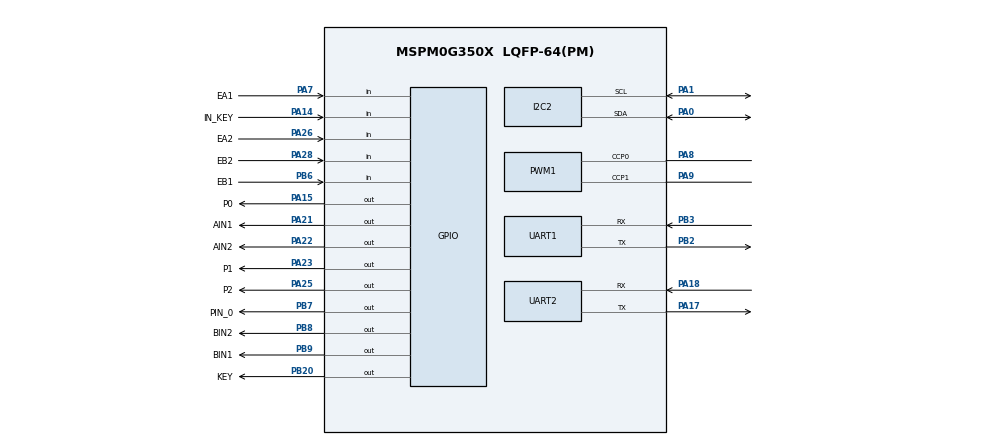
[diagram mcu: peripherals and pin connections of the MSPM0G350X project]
/**
 * @cliArgs --device "MSPM0G350X" --part "Default" --package "LQFP-64(PM)" --product "mspm0_sdk@2.10.00.04"
 * @versions {"tool":"1.27.1+4634"}
 */

/**
 * Import the modules used in this configuration.
 */
const ADC12   = scripting.addModule("/ti/driverlib/ADC12", {}, false);
const ADC121  = ADC12.addInstance();
const GPIO    = scripting.addModule("/ti/driverlib/GPIO", {}, false);
const GPIO1   = GPIO.addInstance();
const GPIO2   = GPIO.addInstance();
const GPIO3   = GPIO.addInstance();
const GPIO4   = GPIO.addInstance();
const GPIO5   = GPIO.addInstance();
const GPIO6   = GPIO.addInstance();
const GPIO7   = GPIO.addInstance();
const I2C     = scripting.addModule("/ti/driverlib/I2C", {}, false);
const I2C1    = I2C.addInstance();
const I2C2    = I2C.addInstance();
const PWM     = scripting.addModule("/ti/driverlib/PWM", {}, false);
const PWM1    = PWM.addInstance();
const SYSCTL  = scripting.addModule("/ti/driverlib/SYSCTL");
const SYSTICK = scripting.addModule("/ti/driverlib/SYSTICK");
const TIMER   = scripting.addModule("/ti/driverlib/TIMER", {}, false);
const TIMER1  = TIMER.addInstance();
const UART    = scripting.addModule("/ti/driverlib/UART", {}, false);
const UART1   = UART.addInstance();
const UART2   = UART.addInstance();

/**
 * Write custom configuration values to the imported modules.
 */
ADC121.$name                             = "ADC_VOLTAGE";
ADC121.sampClkSrc                        = "DL_ADC12_CLOCK_ULPCLK";
ADC121.sampClkDiv                        = "DL_ADC12_CLOCK_DIVIDE_8";
ADC121.repeatMode                        = true;
ADC121.sampleTime0                       = "2us";
ADC121.configureDMA                      = true;
ADC121.sampCnt                           = 1;
ADC121.enabledDMATriggers                = ["DL_ADC12_DMA_MEM0_RESULT_LOADED"];
ADC121.peripheral.adcPin0.$assign        = "PA27";
ADC121.adcPin0Config.hideOutputInversion = scripting.forceWrite(false);
ADC121.adcPin0Config.$name               = "ti_driverlib_gpio_GPIOPinGeneric4";
ADC121.DMA_CHANNEL.$name                 = "DMA_CH0";
ADC121.DMA_CHANNEL.addressMode           = "f2b";
ADC121.DMA_CHANNEL.srcLength             = "HALF_WORD";
ADC121.DMA_CHANNEL.dstLength             = "HALF_WORD";
ADC121.DMA_CHANNEL.configureTransferSize = true;
ADC121.DMA_CHANNEL.transferSize          = 40;
ADC121.DMA_CHANNEL.transferMode          = "FULL_CH_REPEAT_SINGLE";

const Board = scripting.addModule("/ti/driverlib/Board", {}, false);

GPIO1.$name                         = "GPIO_MOTOR";
GPIO1.associatedPins.create(5);
GPIO1.associatedPins[0].$name       = "BIN2";
GPIO1.associatedPins[0].pin.$assign = "PB8";
GPIO1.associatedPins[1].$name       = "BIN1";
GPIO1.associatedPins[1].pin.$assign = "PB9";
GPIO1.associatedPins[2].$name       = "AIN1";
GPIO1.associatedPins[2].pin.$assign = "PA21";
GPIO1.associatedPins[3].$name       = "AIN2";
GPIO1.associatedPins[3].pin.$assign = "PA22";
GPIO1.associatedPins[4].$name       = "PIN_STBY";

GPIO2.$name                         = "Gray_Address";
GPIO2.associatedPins.create(3);
GPIO2.associatedPins[0].$name       = "P0";
GPIO2.associatedPins[0].pin.$assign = "PA15";
GPIO2.associatedPins[1].$name       = "P1";
GPIO2.associatedPins[1].pin.$assign = "PA23";
GPIO2.associatedPins[2].$name       = "P2";
GPIO2.associatedPins[2].pin.$assign = "PA25";

GPIO3.$name                         = "LED";
GPIO3.associatedPins[0].$name       = "KEY";
GPIO3.associatedPins[0].pin.$assign = "PB20";

GPIO4.$name                               = "GRAY_IN";
GPIO4.associatedPins[0].$name             = "IN_KEY";
GPIO4.associatedPins[0].direction         = "INPUT";
GPIO4.associatedPins[0].internalResistor  = "PULL_UP";
GPIO4.associatedPins[0].interruptEn       = true;
GPIO4.associatedPins[0].polarity          = "FALL";
GPIO4.associatedPins[0].interruptPriority = "1";
GPIO4.associatedPins[0].pin.$assign       = "PA14";

GPIO5.$name                               = "ENCODERA";
GPIO5.associatedPins.create(2);
GPIO5.associatedPins[0].$name             = "EA1";
GPIO5.associatedPins[0].direction         = "INPUT";
GPIO5.associatedPins[0].interruptEn       = true;
GPIO5.associatedPins[0].polarity          = "RISE";
GPIO5.associatedPins[0].interruptPriority = "1";
GPIO5.associatedPins[0].internalResistor  = "PULL_UP";
GPIO5.associatedPins[0].pin.$assign       = "PA7";
GPIO5.associatedPins[1].$name             = "EA2";
GPIO5.associatedPins[1].direction         = "INPUT";
GPIO5.associatedPins[1].interruptEn       = true;
GPIO5.associatedPins[1].polarity          = "RISE";
GPIO5.associatedPins[1].interruptPriority = "1";
GPIO5.associatedPins[1].internalResistor  = "PULL_UP";
GPIO5.associatedPins[1].pin.$assign       = "PA26";

GPIO6.$name                               = "ENCODERB";
GPIO6.associatedPins.create(2);
GPIO6.associatedPins[0].$name             = "EB1";
GPIO6.associatedPins[0].direction         = "INPUT";
GPIO6.associatedPins[0].interruptEn       = true;
GPIO6.associatedPins[0].polarity          = "RISE";
GPIO6.associatedPins[0].interruptPriority = "1";
GPIO6.associatedPins[0].internalResistor  = "PULL_UP";
GPIO6.associatedPins[0].pin.$assign       = "PB6";
GPIO6.associatedPins[1].$name             = "EB2";
GPIO6.associatedPins[1].direction         = "INPUT";
GPIO6.associatedPins[1].interruptEn       = true;
GPIO6.associatedPins[1].polarity          = "RISE";
GPIO6.associatedPins[1].interruptPriority = "1";
GPIO6.associatedPins[1].internalResistor  = "PULL_UP";
GPIO6.associatedPins[1].pin.$assign       = "PA28";

GPIO7.$name                         = "BUFFER";
GPIO7.associatedPins[0].$name       = "PIN_0";
GPIO7.associatedPins[0].pin.$assign = "PB7";

I2C1.$name                             = "I2C_OLED";
I2C1.basicEnableController             = true;
I2C1.basicControllerStandardBusSpeed   = "Fast";
I2C1.sdaPinConfig.hideOutputInversion  = scripting.forceWrite(false);
I2C1.sdaPinConfig.onlyInternalResistor = scripting.forceWrite(false);
I2C1.sdaPinConfig.passedPeripheralType = scripting.forceWrite("Digital");
I2C1.sdaPinConfig.$name                = "ti_driverlib_gpio_GPIOPinGeneric7";
I2C1.sclPinConfig.hideOutputInversion  = scripting.forceWrite(false);
I2C1.sclPinConfig.onlyInternalResistor = scripting.forceWrite(false);
I2C1.sclPinConfig.passedPeripheralType = scripting.forceWrite("Digital");
I2C1.sclPinConfig.$name                = "ti_driverlib_gpio_GPIOPinGeneric8";

I2C2.$name                             = "I2C_MPU6050";
I2C2.basicEnableController             = true;
I2C2.basicControllerStandardBusSpeed   = "Fast";
I2C2.peripheral.sdaPin.$assign         = "PA0";
I2C2.peripheral.sclPin.$assign         = "PA1";
I2C2.sdaPinConfig.hideOutputInversion  = scripting.forceWrite(false);
I2C2.sdaPinConfig.onlyInternalResistor = scripting.forceWrite(false);
I2C2.sdaPinConfig.passedPeripheralType = scripting.forceWrite("Digital");
I2C2.sdaPinConfig.$name                = "ti_driverlib_gpio_GPIOPinGeneric9";
I2C2.sclPinConfig.hideOutputInversion  = scripting.forceWrite(false);
I2C2.sclPinConfig.onlyInternalResistor = scripting.forceWrite(false);
I2C2.sclPinConfig.passedPeripheralType = scripting.forceWrite("Digital");
I2C2.sclPinConfig.$name                = "ti_driverlib_gpio_GPIOPinGeneric10";

PWM1.$name                              = "PWM_MOTOR";
PWM1.timerCount                         = 3200;
PWM1.peripheral.$assign                 = "TIMA0";
PWM1.peripheral.ccp0Pin.$assign         = "PA8";
PWM1.peripheral.ccp1Pin.$assign         = "PA9";
PWM1.PWM_CHANNEL_0.$name                = "ti_driverlib_pwm_PWMTimerCC0";
PWM1.PWM_CHANNEL_0.initVal              = "HIGH";
PWM1.PWM_CHANNEL_1.$name                = "ti_driverlib_pwm_PWMTimerCC1";
PWM1.PWM_CHANNEL_1.initVal              = "HIGH";
PWM1.ccp0PinConfig.direction            = scripting.forceWrite("OUTPUT");
PWM1.ccp0PinConfig.hideOutputInversion  = scripting.forceWrite(false);
PWM1.ccp0PinConfig.onlyInternalResistor = scripting.forceWrite(false);
PWM1.ccp0PinConfig.passedPeripheralType = scripting.forceWrite("Digital");
PWM1.ccp0PinConfig.$name                = "ti_driverlib_gpio_GPIOPinGeneric0";
PWM1.ccp1PinConfig.direction            = scripting.forceWrite("OUTPUT");
PWM1.ccp1PinConfig.hideOutputInversion  = scripting.forceWrite(false);
PWM1.ccp1PinConfig.onlyInternalResistor = scripting.forceWrite(false);
PWM1.ccp1PinConfig.passedPeripheralType = scripting.forceWrite("Digital");
PWM1.ccp1PinConfig.$name                = "ti_driverlib_gpio_GPIOPinGeneric1";

SYSCTL.forceDefaultClkConfig = true;

SYSTICK.periodEnable      = true;
SYSTICK.interruptEnable   = true;
SYSTICK.systickEnable     = true;
SYSTICK.period            = 32000;
SYSTICK.interruptPriority = "0";

TIMER1.$name              = "TIMER_Encoder";
TIMER1.timerPeriod        = "10 ms";
TIMER1.timerClkPrescale   = 32;
TIMER1.timerMode          = "PERIODIC";
TIMER1.peripheral.$assign = "TIMA1";

UART1.$name                    = "UART_0";
UART1.enabledInterrupts        = ["RX"];
UART1.targetBaudRate           = 115200;
UART1.peripheral.$assign       = "UART3";
UART1.peripheral.rxPin.$assign = "PB3";
UART1.peripheral.txPin.$assign = "PB2";
UART1.txPinConfig.$name        = "ti_driverlib_gpio_GPIOPinGeneric2";
UART1.rxPinConfig.$name        = "ti_driverlib_gpio_GPIOPinGeneric3";

UART2.$name                    = "UART_1";
UART2.peripheral.rxPin.$assign = "PA18";
UART2.peripheral.txPin.$assign = "PA17";
UART2.txPinConfig.$name        = "ti_driverlib_gpio_GPIOPinGeneric5";
UART2.rxPinConfig.$name        = "ti_driverlib_gpio_GPIOPinGeneric6";

/**
 * Pinmux solution for unlocked pins/peripherals. This ensures that minor changes to the automatic solver in a future
 * version of the tool will not impact the pinmux you originally saw.  These lines can be completely deleted in order to
 * re-solve from scratch.
 */
ADC121.peripheral.$suggestSolution             = "ADC0";
ADC121.DMA_CHANNEL.peripheral.$suggestSolution = "DMA_CH0";
Board.peripheral.$suggestSolution              = "DEBUGSS";
Board.peripheral.swclkPin.$suggestSolution     = "PA20";
Board.peripheral.swdioPin.$suggestSolution     = "PA19";
GPIO1.associatedPins[4].pin.$suggestSolution   = "PB13";
I2C1.peripheral.$suggestSolution               = "I2C1";
I2C1.peripheral.sdaPin.$suggestSolution        = "PA10";
I2C1.peripheral.sclPin.$suggestSolution        = "PA11";
I2C2.peripheral.$suggestSolution               = "I2C0";
SYSCTL.peripheral.$suggestSolution             = "SYSCTL";
UART2.peripheral.$suggestSolution              = "UART1";
